# LPC13Uxx register map
File version: 1
CPU: CM3 r2p1, little endian, no MPU, no FPU, 3 interrupt priority bits
Registers are 32-bit, read-write, reset 0x0 unless marked. A register's access mark holds for its fields unless they carry their own. Offsets are from the block's base; [hi:lo] are bit positions; {n}, {i} and the like mark numbered series; 'fields as' and 'values as' point back to an identical list.

## SYSCON — System control block
Base 0x40048000
0x00 SYSMEMREMAP — System memory remap
  [1:0] MAP — System memory remap. Value 0x3 is reserved.
    0=BOOT_LOADER_MODE_IN (Boot Loader Mode. Interrupt vectors are re-mapped to Boot ROM.); 1=USER_RAM_MODE_INTER (User RAM Mode. Interrupt vectors are re-mapped to Static RAM.); 2=USER_FLASH_MODE_INT (User Flash Mode. Interrupt vectors are not re-mapped and reside in Flash.)
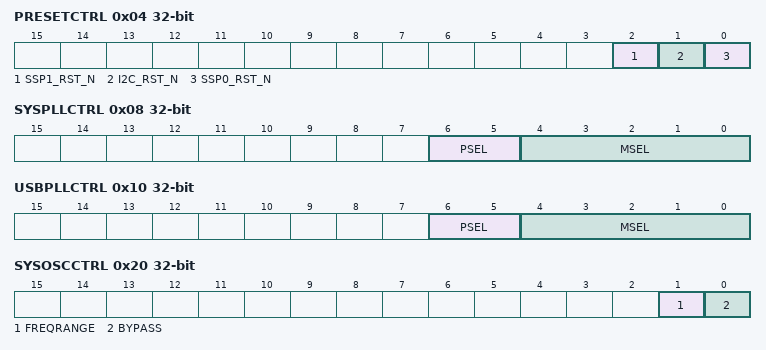
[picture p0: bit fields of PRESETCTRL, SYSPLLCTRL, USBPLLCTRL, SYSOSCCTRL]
0x04 PRESETCTRL — Peripheral reset control
  [2] SSP1_RST_N — SSP1 reset control
    0=RESETS_THE_SSP0_PERI (Resets the SSP0 peripheral.); 1=SSP1_RESET_DE_ASSERT (SSP1 reset de-asserted.)
  [1] I2C_RST_N — I2C reset control
    0=RESETS_THE_I2C_PERIP (Resets the I2C peripheral.); 1=I2C_RESET_DE_ASSERTE (I2C reset de-asserted.)
  [0] SSP0_RST_N — SSP0 reset control
    0=RESETS_THE_SSP0_PERI (Resets the SSP0 peripheral.); 1=SSP0_RESET_DE_ASSERT (SSP0 reset de-asserted.)
0x08 SYSPLLCTRL — System PLL control
  [6:5] PSEL — Post divider ratio P. The division ratio is 2 x P.
    0=P_EQ_1 (P = 1); 1=P_EQ_2 (P = 2); 2=P_EQ_4 (P = 4); 3=P_EQ_8 (P = 8)
  [4:0] MSEL — Feedback divider value. The division value M is the programmed MSEL value + 1. 00000: Division ratio M = 1 to 11111: Division ratio M = 32
0x0C SYSPLLSTAT ro — System PLL status
  [0] LOCK — PLL lock status
    0=PLL_NOT_LOCKED; 1=PLL_LOCKED
0x10 USBPLLCTRL — USB PLL control
  fields as SYSPLLCTRL
0x14 USBPLLSTAT ro — USB PLL status
  [0] LOCK — PLL lock status
    0=PLL_NOT_LOCKED; 1=PLL_LOCKED
0x20 SYSOSCCTRL — System oscillator control
  [1] FREQRANGE — Determines frequency range for Low-power oscillator.
    0=1_20_MHZ_FREQUENCY (1 - 20 MHz frequency range.); 1=15_25_MHZ_FREQUENC (15 - 25 MHz frequency range)
  [0] BYPASS — Bypass system oscillator
    0=OSCILLATOR_IS_NOT_BY (Oscillator is not bypassed.); 1=BYPASS_ENABLED_PLL_ (Bypass enabled. PLL input (sys_osc_clk) is fed directly from the XTALIN pin bypassing the oscillator. Use this mode when using an external clock source instead of the crystal oscillator.)
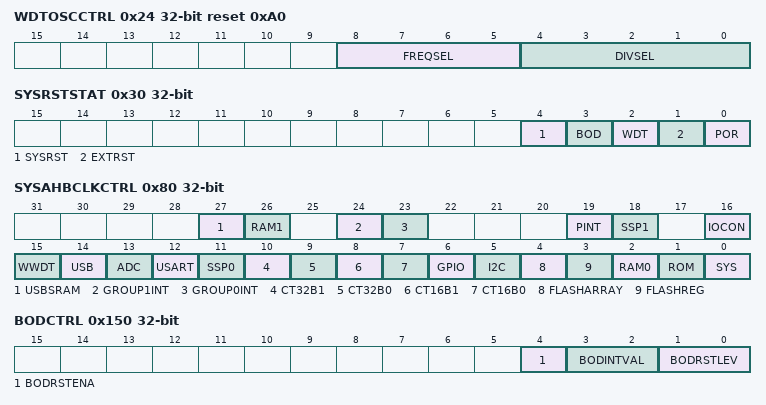
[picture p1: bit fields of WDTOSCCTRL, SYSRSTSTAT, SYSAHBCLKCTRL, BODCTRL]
0x24 WDTOSCCTRL reset 0xA0 — Watchdog oscillator control
  [8:5] FREQSEL — Select watchdog oscillator analog output frequency (Fclkana).
    1=0_6_MHZ; 2=1_05_MHZ; 3=1_4_MHZ; 4=1_75_MHZ; 5=2_1_MHZ; 6=2_4_MHZ; 7=2_7_MHZ; 8=3_0_MHZ; 9=3_25_MHZ; 10=3_5_MHZ; 11=3_75_MHZ; 12=4_0_MHZ; 13=4_2_MHZ; 14=4_4_MHZ; 15=4_6_MHZ
  [4:0] DIVSEL — Select divider for Fclkana. wdt_osc_clk = Fclkana/ (2 x (1 + DIVSEL)) 00000: 2 x (1 + DIVSEL) = 2 00001: 2 x (1 + DIVSEL) = 4 to 11111: 2 x (1 + DIVSEL) = 64
0x30 SYSRSTSTAT — System reset status register
  [4] SYSRST — Status of the software system reset
    0=NO_SYSTEM_RESET_DETE (No System reset detected); 1=SYSTEM_RESET_DETECTE (System reset detected)
  [3] BOD — Status of the Brown-out detect reset
    0=NO_BOD_RESET_DETECTE (No BOD reset detected); 1=BOD_RESET_DETECTED
  [2] WDT — Status of the Watchdog reset
    0=NO_WDT_RESET_DETECTE (No WDT reset detected); 1=WDT_RESET_DETECTED
  [1] EXTRST — Status of the external RESET pin
    0=NO_RESET_EVENT_DETEC (No reset event detected); 1=RESET_DETECTED
  [0] POR — POR reset status
    0=NO_POR_DETECTED; 1=POR_DETECTED
0x40 SYSPLLCLKSEL — System PLL clock source select
  [1:0] SEL — System PLL clock source
    0=IRC; 1=CRYSTAL_OSCILLATOR_ (Crystal Oscillator (SYSOSC))
0x48 USBPLLCLKSEL — USB PLL clock source select
  [1:0] SEL — USB PLL clock source
    0=IRC_THE_USB_PLL_CLO (IRC. The USB PLL clock source must be switched to system oscillator for correct USB operation.); 1=SYSTEM_OSCILLATOR
0x70 MAINCLKSEL — Main clock source select
  [1:0] SEL — Clock source for main clock
    0=IRC_OSCILLATOR; 1=PLL_INPUT; 2=WATCHDOG_OSCILLATOR; 3=PLL_OUTPUT
0x78 SYSAHBCLKDIV reset 0x1 — System clock divider
  [7:0] DIV — System AHB clock divider values 0: System clock disabled. 1: Divide by 1. to 255: Divide by 255.
0x80 SYSAHBCLKCTRL reset not defined — System clock control
  [27] USBSRAM — Enables USB SRAM block located at 0x2000 4000 to 0x2000 4800.
    0=DISABLE; 1=ENABLE
  [26] RAM1 — Enables clock for SRAM1 located at 0x2000 0000 to 0x2000 0800.
    0=DISABLE; 1=ENABLE
  [24] GROUP1INT — Enables clock to GPIO GROUP1 interrupt register interface.
    0=DISABLE; 1=ENABLE
  [23] GROUP0INT — Enables clock to GPIO GROUP0 interrupt register interface.
    0=DISABLE; 1=ENABLE
  [19] PINT — Enables clock to GPIO Pin interrupts register interface.
    0=DISABLE; 1=ENABLE
  [18] SSP1 — Enables clock for SSP1.
    0=DISABLE; 1=ENABLE
  [16] IOCON — Enables clock for I/O configuration block.
    0=DISABLE; 1=ENABLE
  [15] WWDT — Enables clock for WWDT.
    0=DISABLE; 1=ENABLE
  [14] USB — Enables clock to the USB register interface.
    0=DISABLE; 1=ENABLE
  [13] ADC — Enables clock for ADC.
    0=DISABLE; 1=ENABLE
  [12] USART — Enables clock for UART.
    0=DISABLE; 1=ENABLE
  [11] SSP0 — Enables clock for SSP0.
    0=DISABLE; 1=ENABLE
  [10] CT32B1 — Enables clock for 32-bit counter/timer 1.
    0=DISABLE; 1=ENABLE
  [9] CT32B0 — Enables clock for 32-bit counter/timer 0.
    0=DISABLE; 1=ENABLE
  [8] CT16B1 — Enables clock for 16-bit counter/timer 1.
    0=DISABLE; 1=ENABLE
  [7] CT16B0 — Enables clock for 16-bit counter/timer 0.
    0=DISABLE; 1=ENABLE
  [6] GPIO — Enables clock for GPIO port registers.
    0=DISABLE; 1=ENABLE
  [5] I2C — Enables clock for I2C.
    0=DISABLE; 1=ENABLE
  [4] FLASHARRAY — Enables clock for flash array access.
    0=DISABLED; 1=ENABLED
  [3] FLASHREG — Enables clock for flash register interface.
    0=DISABLED; 1=ENABLED
  [2] RAM0 — Enables clock for SRAM0.
    0=DISABLE; 1=ENABLE
  [1] ROM — Enables clock for ROM.
    0=DISABLE; 1=ENABLE
  [0] SYS — Enables the clock for the AHB, the APB bridge, the Cortex-M3 FCLK and HCLK, SysCon, and the PMU. This bit is read only and always reads as 1.
    1=ENABLE
0x94 SSP0CLKDIV — SSP0 clock divider
  [7:0] DIV — SPI0_PCLK clock divider values. 0: System clock disabled. 1: Divide by 1. to 255: Divide by 255.
0x98 UARTCLKDIV — UART clock divider
  [7:0] DIV — UART_PCLK clock divider values 0: Disable UART_PCLK. 1: Divide by 1. to 255: Divide by 255.
0x9C SSP1CLKDIV — SSP1 clock divider
  [7:0] DIV — SSP1_PCLK clock divider values 0: Disable SSP1_PCLK. 1: Divide by 1. to 255: Divide by 255.
0xAC TRACECLKDIV — ARM trace clock divider
  [7:0] DIV — ARM trace clock divider values. 0: Disable TRACE_CLK. 1: Divide by 1. to 255: Divide by 255.
0xB0 SYSTICKCLKDIV — SYSTICK clock divider
  [7:0] DIV — SYSTICK clock divider values. 0: Disable SYSTICK timer clock. 1: Divide by 1. to 255: Divide by 255.
0xC0 USBCLKSEL — USB clock source select
  [1:0] SEL — USB clock source. Values 0x2 and 0x3 are reserved.
    0=USB_PLL_OUT; 1=MAIN_CLOCK
0xC8 USBCLKDIV — USB clock source divider
  [7:0] DIV — USB clock divider values 0: Disable USB clock. 1: Divide by 1. to 255: Divide by 255.
0xE0 CLKOUTSEL — CLKOUT clock source select
  [1:0] SEL — CLKOUT clock source
    0=IRC_OSCILLATOR; 1=CRYSTAL_OSCILLATOR_ (Crystal oscillator (SYSOSC)); 2=WATCHDOG_OSCILLATOR; 3=MAIN_CLOCK
0xE8 CLKOUTDIV — CLKOUT clock divider
  [7:0] DIV — CLKOUT clock divider values 0: Disable CLKOUT clock divider. 1: Divide by 1. to 255: Divide by 255.
0x100 PIOPORCAP0 ro reset not defined — POR captured PIO status 0
  [23:0] PIOSTAT — State of P0_23 through P0_0 at power-on reset
0x104 PIOPORCAP1 ro reset not defined — POR captured PIO status 1
  [31:0] PIOSTAT — State of P1_31 through P1_0 at power-on reset
0x150 BODCTRL — Brown-Out Detect
  [4] BODRSTENA — BOD reset enable
    0=DISABLE_RESET_FUNCTI (Disable reset function.); 1=ENABLE_RESET_FUNCTIO (Enable reset function.)
  [3:2] BODINTVAL — BOD interrupt level
    1=LEVEL_1THE_INTERRUP (Level 1:The interrupt assertion threshold voltage is 2.22 V; the interrupt de-assertion threshold voltage is 2.35 V.); 2=LEVEL_2_THE_INTERRU (Level 2: The interrupt assertion threshold voltage is 2.52 V; the interrupt de-assertion threshold voltage is 2.66 V.); 3=LEVEL_3_THE_INTERRU (Level 3: The interrupt assertion threshold voltage is 2.80 V; the interrupt de-assertion threshold voltage is 2.90 V.)
  [1:0] BODRSTLEV — BOD reset level
    0=LEVEL_0_THE_RESET_A (Level 0: The reset assertion threshold voltage is 1.46 V; the reset de-assertion threshold voltage is 1.63 V.); 1=LEVEL_1_THE_RESET_A (Level 1: The reset assertion threshold voltage is 2.06 V; the reset de-assertion threshold voltage is 2.15 V.); 2=LEVEL_2_THE_RESET_A (Level 2: The reset assertion threshold voltage is 2.35 V; the reset de-assertion threshold voltage is 2.43 V.); 3=LEVEL_3_THE_RESET_A (Level 3: The reset assertion threshold voltage is 2.63 V; the reset de-assertion threshold voltage is 2.71 V.)
0x154 SYSTCKCAL reset not defined — System tick counter calibration
  [25:0] CAL — System tick timer calibration value
0x170 IRQLATENCY reset 0x10 — IQR delay. Allows trade-off between interrupt latency and determinism.
  [7:0] LATENCY — 8-bit latency value
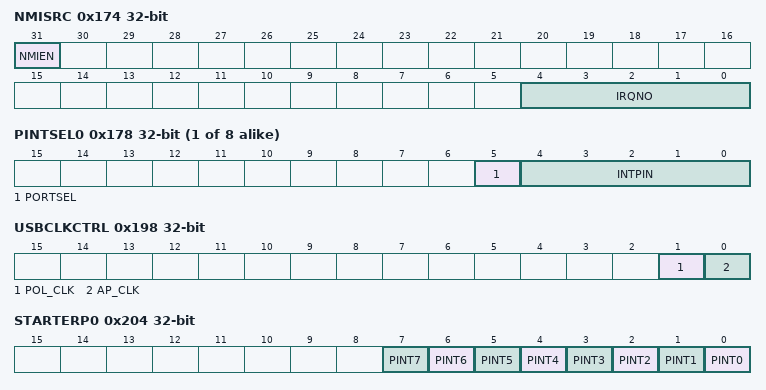
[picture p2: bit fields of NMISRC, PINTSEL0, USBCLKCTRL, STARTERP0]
0x174 NMISRC — NMI Source Control
  [31] NMIEN — Write a 1 to this bit to enable the Non-Maskable Interrupt (NMI) source selected by bits 4:0.
  [4:0] IRQNO — The IRQ number of the interrupt that acts as the Non-Maskable Interrupt (NMI) if bit 31 is 1. See Table 53 for the list of interrupt sources and their IRQ numbers.
{0x178+4i} PINTSEL{i} (i=0..7) — GPIO Pin Interrupt Select register
  [5] PORTSEL — Select the port for the pin number to be selected in the INTPIN bits of this register.
    0=PORT_0; 1=PORT_1
  [4:0] INTPIN — Pin number within the port selected by the PORTSEL bit in this register.
0x198 USBCLKCTRL reset not defined — USB clock control
  [1] POL_CLK — USB need_clock polarity for triggering the USB wake-up interrupt
    0=FALLING_EDGE_OF_THE_ (Falling edge of the USB need_clock triggers the USB wake-up (default).); 1=RISING_EDGE_OF_THE_U (Rising edge of the USB need_clock triggers the USB wake-up.)
  [0] AP_CLK — USB need_clock signal control
    0=UNDER_HARDWARE_CONTR (Under hardware control.); 1=FORCED_HIGH_
0x19C USBCLKST ro reset not defined — USB clock status
  [0] NEED_CLKST — USB need_clock signal status
    0=LOW; 1=HIGH
0x204 STARTERP0 — Start logic 0 interrupt wake-up enable register 0
  [all] fields
    0=DISABLED; 1=ENABLED
  [n] PINT{n} (n=0..7) — Pin interrupt {n} wake-up
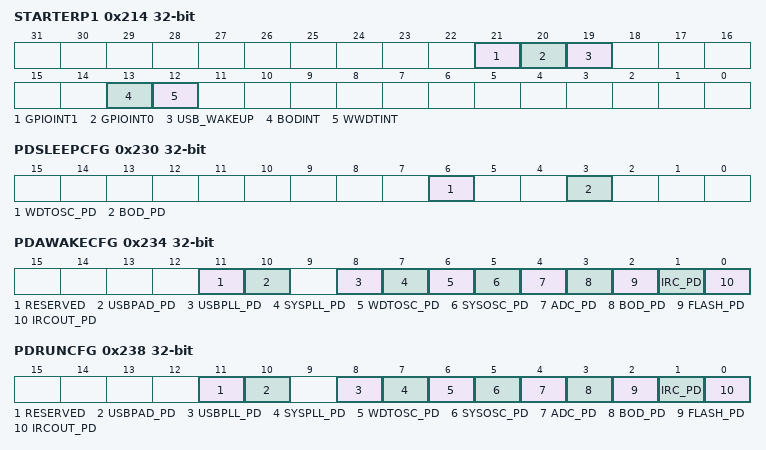
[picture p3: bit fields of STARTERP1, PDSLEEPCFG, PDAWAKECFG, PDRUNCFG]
0x214 STARTERP1 — Start logic 1 interrupt wake-up enable register 1
  [all] fields
    0=DISABLED; 1=ENABLED
  [21] GPIOINT1 — GPIO GROUP1 interrupt wake-up
  [20] GPIOINT0 — GPIO GROUP0 interrupt wake-up
  [19] USB_WAKEUP — USB need_clock signal wake-up
  [13] BODINT — Brown Out Detect (BOD) interrupt wake-up
  [12] WWDTINT — WWDT interrupt wake-up
0x230 PDSLEEPCFG reset not defined — Power-down states in deep-sleep mode
  [6] WDTOSC_PD — Watchdog oscillator power-down control for Deep-sleep and Power-down mode
    1=POWERED_DOWN; 0=POWERED
  [3] BOD_PD — BOD power-down control for Deep-sleep and Power-down mode
    1=POWERED_DOWN; 0=POWERED
0x234 PDAWAKECFG reset not defined — Power-down states for wake-up from deep-sleep
  [11] RESERVED — Reserved. This bit must be set to one in Run mode.
  [10] USBPAD_PD — USB transceiver wake-up configuration
    0=USB_TRANSCEIVER_POWER_UP (USB transceiver powered); 1=USB_TRANSCEIVER_POWER_DOWN (USB transceiver powered down)
  [8] USBPLL_PD — USB PLL wake-up configuration
    0=POWERED; 1=POWERED_DOWN
  [7] SYSPLL_PD — System PLL wake-up configuration
    1=POWERED_DOWN; 0=POWERED
  [6] WDTOSC_PD — Watchdog oscillator wake-up configuration
    1=POWERED_DOWN; 0=POWERED
  [5] SYSOSC_PD — Crystal oscillator wake-up configuration
    1=POWERED_DOWN; 0=POWERED
  [4] ADC_PD — ADC wake-up configuration
    1=POWERED_DOWN; 0=POWERED
  [3] BOD_PD — BOD wake-up configuration
    1=POWERED_DOWN; 0=POWERED
  [2] FLASH_PD — Flash wake-up configuration
    1=POWERED_DOWN; 0=POWERED
  [1] IRC_PD — IRC oscillator power-down wake-up configuration
    1=POWERED_DOWN; 0=POWERED
  [0] IRCOUT_PD — IRC oscillator output wake-up configuration
    1=POWERED_DOWN; 0=POWERED
0x238 PDRUNCFG reset not defined — Power configuration register
  [11] RESERVED — Reserved. This bit must be set to one in Run mode.
  [10] USBPAD_PD — USB transceiver power-down configuration
    0=USB_TRANSCEIVER_POWER_UP (USB transceiver powered); 1=USB_TRANSCEIVER_POWER_DOWN_SUSPEND (USB transceiver powered down (suspend mode))
  [8] USBPLL_PD — USB PLL power-down
    0=POWERED; 1=POWERED_DOWN
  [7] SYSPLL_PD — System PLL power-down
    1=POWERED_DOWN; 0=POWERED
  [6] WDTOSC_PD — Watchdog oscillator power-down
    1=POWERED_DOWN; 0=POWERED
  [5] SYSOSC_PD — Crystal oscillator power-down
    1=POWERED_DOWN; 0=POWERED
  [4] ADC_PD — ADC power-down
    1=POWERED_DOWN; 0=POWERED
  [3] BOD_PD — BOD power-down
    1=POWERED_DOWN; 0=POWERED
  [2] FLASH_PD — Flash power-down
    1=POWERED_DOWN; 0=POWERED
  [1] IRC_PD — IRC oscillator power-down
    1=POWERED_DOWN; 0=POWERED
  [0] IRCOUT_PD — IRC oscillator output power-down
    1=POWERED_DOWN; 0=POWERED
0x3F8 DEVICE_ID ro reset not defined
  [31:0] DEVICEID — LPC1345FHN33 = 0x2801 0541 LPC1345FBD48 = 0x2801 0541 LPC1346FHN33 = 0x0801 8542 LPC1346FBD48 = 0x0801 8542 LPC1347FHN33 = 0x0802 0543 LPC1347FBD48 = 0x0802 0543 LPC1347FBD64 = 0x0802 0543 LPC1315FHN33 = 0x3A01 0523 LPC1315FBD48 = 0x3A01 0523 LPC1316FHN33 = 0x1A01 8524 LPC1316FBD48 = 0x1A01 8524 LPC1317FHN33 = 0x1A02 0525 LPC1317FBD48 = 0x1A02 0525 LPC1317FBD64 = 0x1A02 0525
